# CPU_NVIC register map
Vendor: Texas Instruments
Peripheral module from a debugger description file (folder CC26x4).
Registers are 32-bit, read-write, reset 0x0 unless marked. A register's access mark holds for its fields unless they carry their own. Offsets are as the file gives them; lines under a group give offsets from that group; [hi:lo] are bit positions; {n}, {i} and the like mark numbered series; 'fields as' and 'values as' point back to an identical list; <NAME> marks a mode.

## CPU_NVIC — Cortex-M's Nested Vectored Interrupt Controller (NVIC)
0x00 ISER0 ro — Enables or reads the enabled state of each group of 32 interrupts
  [31:0] SETENA — For SETENA[m] in NVIC_ISER*n, indicates whether interrupt 32*n + m is enabled
0x04 ISER1 ro — Enables or reads the enabled state of each group of 32 interrupts
  [15:0] SETENA — For SETENA[m] in NVIC_ISER*n, indicates whether interrupt 32*n + m is enabled
0x80 ICER0 ro — Clears or reads the enabled state of each group of 32 interrupts
  [31:0] CLRENA — For CLRENA[m] in NVIC_ICER*n, indicates whether interrupt 32*n + m is enabled
0x84 ICER1 ro — Clears or reads the enabled state of each group of 32 interrupts
  [15:0] CLRENA — For CLRENA[m] in NVIC_ICER*n, indicates whether interrupt 32*n + m is enabled
0x100 ISPR0 ro — Enables or reads the pending state of each group of 32 interrupts
  [31:0] SETPEND — For SETPEND[m] in NVIC_ISPR*n, indicates whether interrupt 32*n + m is pending
0x104 ISPR1 ro — Enables or reads the pending state of each group of 32 interrupts
  [15:0] SETPEND — For SETPEND[m] in NVIC_ISPR*n, indicates whether interrupt 32*n + m is pending
0x180 ICPR0 ro — Clears or reads the pending state of each group of 32 interrupts
  [31:0] CLRPEND — For CLRPEND[m] in NVIC_ICPR*n, indicates whether interrupt 32*n + m is pending
0x184 ICPR1 ro — Clears or reads the pending state of each group of 32 interrupts
  [15:0] CLRPEND — For CLRPEND[m] in NVIC_ICPR*n, indicates whether interrupt 32*n + m is pending
0x200 IABR0 ro — For each group of 32 interrupts, shows the active state of each interrupt
  [31:0] ACTIVE — For ACTIVE[m] in NVIC_IABR*n, indicates the active state for interrupt 32*n+m
0x204 IABR1 ro — For each group of 32 interrupts, shows the active state of each interrupt
  [15:0] ACTIVE — For ACTIVE[m] in NVIC_IABR*n, indicates the active state for interrupt 32*n+m
0x280 ITNS0 — For each group of 32 interrupts, determines whether each interrupt targets Non-secure or Secure state
  [31:0] ITNS — For ITNS[m] in NVIC_ITNS*n, the target Security state for interrupt 32*n+m
0x284 ITNS1 access per field — For each group of 32 interrupts, determines whether each interrupt targets Non-secure or Secure state
  [15:0] ITNS rw — For ITNS[m] in NVIC_ITNS*n, the target Security state for interrupt 32*n+m
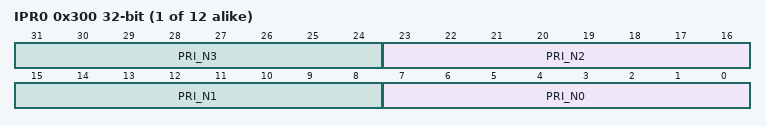
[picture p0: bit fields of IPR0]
{0x300+4i} IPR{i} (i=0..11) — Sets or reads interrupt priorities
  [8n+7:8n] PRI_N{n} (n=0..3) — For register NVIC_IPR*{i}, the priority of interrupt number 4*{i}+{n}, or is RES0 if the PE does not implement this interrupt
